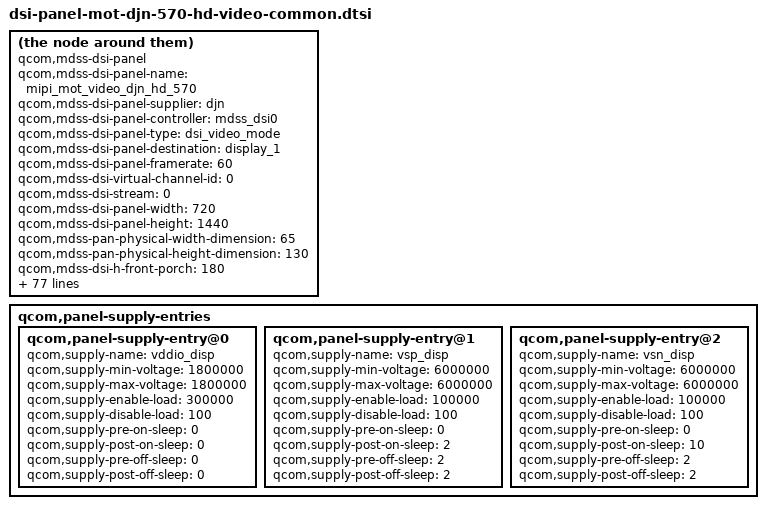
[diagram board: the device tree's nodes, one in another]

compatible = "qcom,mdss-dsi-panel";
qcom,mdss-dsi-panel-name = "mipi_mot_video_djn_hd_570";
qcom,mdss-dsi-panel-supplier = "djn";
qcom,mdss-dsi-panel-controller = <&mdss_dsi0>;
qcom,mdss-dsi-panel-type = "dsi_video_mode";
qcom,mdss-dsi-panel-destination = "display_1";
qcom,mdss-dsi-panel-framerate = <60>;
qcom,mdss-dsi-virtual-channel-id = <0>;
qcom,mdss-dsi-stream = <0>;
qcom,mdss-dsi-panel-width = <720>;
qcom,mdss-dsi-panel-height = <1440>;
qcom,mdss-pan-physical-width-dimension = <65>;
qcom,mdss-pan-physical-height-dimension = <130>;

qcom,mdss-dsi-h-front-porch = <180>;
qcom,mdss-dsi-h-back-porch = <20>;
qcom,mdss-dsi-h-pulse-width = <8>;
qcom,mdss-dsi-h-sync-skew = <0>;
qcom,mdss-dsi-v-back-porch = <6>;
qcom,mdss-dsi-v-front-porch = <172>;
qcom,mdss-dsi-v-pulse-width = <2>;
qcom,mdss-dsi-h-left-border = <0>;
qcom,mdss-dsi-h-right-border = <0>;
qcom,mdss-dsi-v-top-border = <0>;
qcom,mdss-dsi-v-bottom-border = <0>;
qcom,mdss-dsi-bpp = <24>;
qcom,mdss-dsi-underflow-color = <0xff>;
qcom,mdss-dsi-border-color = <0>;

qcom,mdss-dsi-reset-sequence = <1 1>, <0 10>, <1 50>;
qcom,mdss-dsi-dis-reset-sequence = <1 10>, <0 0>;

qcom,mdss-dsi-on-command = [
	39 00 00 00 00 00 03 51 0C F4
	39 01 00 00 00 00 04 B9 83 10 2B
	39 01 00 00 00 00 05 C9 04 07 D0 00
	15 00 00 00 00 00 02 53 24
	15 00 00 00 00 00 02 55 01
	05 01 00 00 78 00 01 11
	05 01 00 00 14 00 01 29];		/* Display on */

qcom,mdss-dsi-off-command = [
	05 01 00 00 14 00 01 28
	05 01 00 00 78 00 01 10];

qcom,mdss-dsi-on-command-state = "dsi_lp_mode";
qcom,mdss-dsi-off-command-state = "dsi_lp_mode";

qcom,mdss-dsi-cabc-ui-command = [15 01 00 00 00 00 02 55 01];
qcom,mdss-dsi-cabc-ui-command-state = "dsi_hs_mode";
qcom,mdss-dsi-cabc-mv-command = [15 01 00 00 00 00 02 55 03];
qcom,mdss-dsi-cabc-mv-command-state = "dsi_hs_mode";
qcom,mdss-dsi-cabc-dis-command = [15 01 00 00 00 00 02 55 00];
qcom,mdss-dsi-cabc-dis-command-state = "dsi_hs_mode";
qcom,mdss-dsi-hbm-on-command = [39 01 00 00 00 00 03 51 0F FF];
qcom,mdss-dsi-hbm-on-command-state = "dsi_hs_mode";
qcom,mdss-dsi-hbm-off-command = [39 01 00 00 00 00 03 51 0C F4];
qcom,mdss-dsi-hbm-off-command-state = "dsi_hs_mode";
qcom,mdss-dsi-hbm-type = "lcd-dcs-wled";

qcom,mdss-dsi-h-sync-pulse = <0>;
qcom,mdss-dsi-traffic-mode = "burst_mode";
qcom,mdss-dsi-bllp-eof-power-mode;
qcom,mdss-dsi-bllp-power-mode;
qcom,mdss-dsi-hfp-power-mode;
qcom,mdss-dsi-lp11-init;
qcom,mdss-dsi-tx-eot-append;
qcom,mdss-dsi-dma-trigger = "trigger_sw";
qcom,mdss-dsi-mdp-trigger = "none";
qcom,mdss-dsi-lane-0-state;
qcom,mdss-dsi-lane-1-state;
qcom,mdss-dsi-lane-2-state;
qcom,mdss-dsi-lane-3-state;

qcom,mdss-dsi-panel-timings = [98 22 16 00 4a 4c 1a 26 1a 03 04 00];
qcom,mdss-dsi-t-clk-post = <0x04>;
qcom,mdss-dsi-t-clk-pre = <0x1e>;

qcom,mdss-dsi-bl-min-level = <1>;
qcom,mdss-dsi-bl-max-level = <4095>;
qcom,mdss-dsi-bl-pmic-control-type = "bl_ctrl_wled";

qcom,cont-splash-enabled;
qcom,esd-check-enabled;
qcom,mdss-dsi-panel-status-check-mode = "reg_read";
qcom,mdss-dsi-panel-status-command = [06 01 00 01 05 00 01 0A
				06 01 00 01 05 00 01 09
				06 01 00 01 05 00 01 D5];
qcom,mdss-dsi-panel-status-command-state = "dsi_lp_mode";
qcom,mdss-dsi-panel-status-read-length = <4 4 10>;
qcom,mdss-dsi-panel-status-valid-params = <1 3 10>;
qcom,mdss-dsi-panel-status-value = <0x9D 0x80 0x73 0x04 0x20 0x21 0x24 0x25 0x18 0x18 0x18 0x18 0x26 0x27>;
qcom,mdss-dsi-panel-on-check-value = <0x9d>;

qcom,panel-supply-entries {
	#address-cells = <1>;
	#size-cells = <0>;
	qcom,panel-supply-entry@0 {
		qcom,supply-name = "vddio_disp";
		qcom,supply-min-voltage = <1800000>;
		qcom,supply-max-voltage = <1800000>;
		qcom,supply-enable-load = <300000>;
		qcom,supply-disable-load = <100>;
		qcom,supply-pre-on-sleep = <0>;
		qcom,supply-post-on-sleep = <0>;
		qcom,supply-pre-off-sleep = <0>;
		qcom,supply-post-off-sleep = <0>;
	};
	qcom,panel-supply-entry@1 {
		qcom,supply-name = "vsp_disp";
		qcom,supply-min-voltage = <6000000>;
		qcom,supply-max-voltage = <6000000>;
		qcom,supply-enable-load = <100000>;
		qcom,supply-disable-load = <100>;
		qcom,supply-pre-on-sleep = <0>;
		qcom,supply-post-on-sleep = <2>;
		qcom,supply-pre-off-sleep = <2>;
		qcom,supply-post-off-sleep = <2>;
	};
	qcom,panel-supply-entry@2 {
		qcom,supply-name = "vsn_disp";
		qcom,supply-min-voltage = <6000000>;
		qcom,supply-max-voltage = <6000000>;
		qcom,supply-enable-load = <100000>;
		qcom,supply-disable-load = <100>;
		qcom,supply-pre-on-sleep = <0>;
		qcom,supply-post-on-sleep = <10>;
		qcom,supply-pre-off-sleep = <2>;
		qcom,supply-post-off-sleep = <2>;
	};
};
